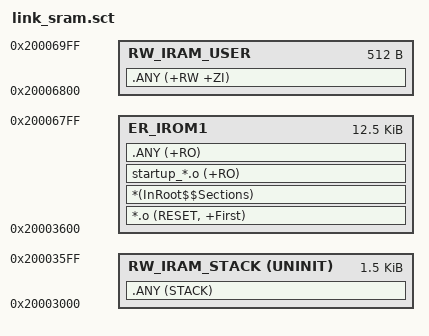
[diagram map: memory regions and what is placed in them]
; *************************************************************
; *** Scatter-Loading Description File generated by uVision ***
; *************************************************************

LR_IROM1 0x20003600 0x3200  {  ; load region size_region: 18KB 
	ER_IROM1 0x20003600 0x3200  {  ; load address = execution address, size = 18KB
		*.o (RESET, +First)
		*(InRoot$$Sections)
		startup_*.o (+RO)
		.ANY (+RO)
	}
  
	RW_IRAM_USER 0x20006800 0x200     {  ; RW & ZI data
		.ANY (+RW +ZI)
	}

	RW_IRAM_STACK 0x20003600-0x600 UNINIT 0x600 {  ; Stack
		.ANY (STACK)
	}
}


